# nrf54h20_engb_application register map
Vendor: Nordic Semiconductor; Series: nRF54h; File version: 1
CPU: CM33 r0p4, little endian, MPU, FPU, 3 interrupt priority bits, 480 interrupts, 8 SAU regions
Registers are 32-bit, read-write, reset 0x0 unless marked. A register's access mark holds for its fields unless they carry their own. Offsets are from the block's base; [hi:lo] are bit positions; lines under a group give offsets from that group; 'fields as' and 'values as' point back to an identical list.

## HSFLL_S — HSFLL
Base 0x5200D000
0x00 TASKS_START wo — Start the HSFLL
  [0] TASKS_START
    1=Trigger task
0x04 TASKS_STOP wo — Stop the HSFLL
  [0] TASKS_STOP
    1=Trigger task
0x10 TASKS_FREQMEAS wo — Start frequency measurement in software-controlled mode
  [0] TASKS_FREQMEAS
    1=Trigger task
0x14 TASKS_FREQCHANGE wo — Trigger frequency change
  [0] TASKS_FREQCHANGE
    1=Trigger task
0x100 EVENTS_STARTED — HSFLL started
  [0] EVENTS_STARTED
    0=NotGenerated (Event not generated); 1=Generated (Event generated)
0x104 EVENTS_STOPPED — HSFLL stopped
  [0] EVENTS_STOPPED
    values as EVENTS_STARTED.EVENTS_STARTED
0x10C EVENTS_FREQMDONE — Frequency measurement done
  [0] EVENTS_FREQMDONE
    values as EVENTS_STARTED.EVENTS_STARTED
0x110 EVENTS_FREQCHANGED — Frequency change done
  [0] EVENTS_FREQCHANGED
    values as EVENTS_STARTED.EVENTS_STARTED
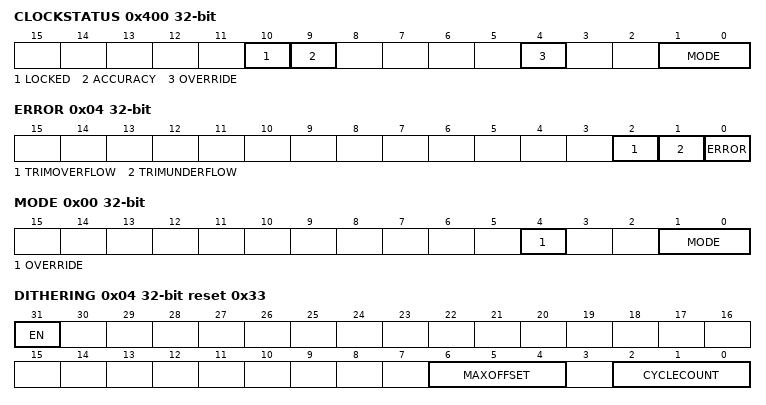
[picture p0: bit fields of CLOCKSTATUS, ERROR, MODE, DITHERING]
0x400 CLOCKSTATUS ro
  [10] LOCKED — The HSFLL lock status.
    0=Not locked to reference clock; 1=Locked to reference clock
  [9] ACCURACY — Clock accuracy.
    0=OutsideLimit (Clock accuracy is outside 2 percent.); 1=WithinLimit (Clock accuracy is within 2 percent.)
  [4] OVERRIDE — HSFLL Override mode.
    0=Disabled (Override mode disabled.); 1=Enabled (Override mode enabled.)
  [1:0] MODE — The HSFLL operating mode.
    0=Open loop mode; 1=Closed loop mode; 2=Bypass mode
0x420 FREQM group — Unspecified
  0x00 DONE ro — Frequency measurement done status
    [0] DONE — Measurement done.
      0=InProgress (Frequency measurement is in progress.); 1=Completed (Frequency measurement is completed.)
  0x04 ERROR ro — Frequency measurement error status
    [2] TRIMOVERFLOW — Overflow error status.
      1=OutsideLimit (Overflow); 0=WithinLimit (No overflow)
    [1] TRIMUNDERFLOW — Underflow error status.
      1=OutsideLimit (Underflow); 0=WithinLimit (No underflow)
    [0] ERROR — Trim error status.
      1=OutsideLimit (Frequency exceeded the accuracy 2 percent in closed loop mode.); 0=WithinLimit (Frequency stayed within accuracy 2 percent in closed loop mode.)
  0x08 MEAS ro — Frequency measurement
    [7:0] VALUE — Last frequency measurement value.
0x440 TRIM group — Unspecified
  0x00 VSUP reset 0x10 — Internal regulator voltage supply level trimming
    [4:0] VALUE — Trim value
  0x04 COARSE reset 0x4 — Coarse frequency trimming
    [9:0] VALUE — Coarse frequency trimming value.
  0x08 FINE reset 0x1E — Fine frequency trimming
    [10:0] VALUE — Fine frequency trimming value
  0x10 TCOEF — Temperature coefficient trimming
    [3:0] VALUE — Trim value.
0x460 CLOCKCTRL group — Unspecified
  0x00 MODE — Clock control
    [4] OVERRIDE — HSFLL override mode.
      values as CLOCKSTATUS.OVERRIDE
    [1:0] MODE — The HSFLL operating mode.
      0=Auto (The PCGC controls the mode automatically.); 1=Open loop mode; 2=Closed loop mode; 3=Bypass mode
  0x04 DITHERING reset 0x33 — Clock dithering configuration
    [31] EN — Enable the clock dithering
      0=Disabled (Clock dithering is disabled); 1=Enabled (Clock dithering is enabled)
    [6:4] MAXOFFSET — Maximum offset configuration for clock dithering
    [2:0] CYCLECOUNT — Cycle count configuration for clock dithering
  0x08 MULT reset 0x4 — Multiplication factor
    [4:0] VAL — Multiplication factor value. Valid range: 4 to 25. Output frequency is a multiplication of 16 MHz reference and the multiplication factor.
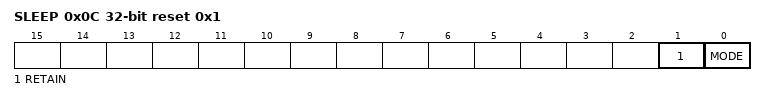
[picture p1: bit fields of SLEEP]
  0x0C SLEEP reset 0x1 — Sleep configuration
    [1] RETAIN
      0=Disabled (No retention while powered down); 1=Enabled (Retain all inputs while powered down)
    [0] MODE — HSFLL sleep mode.
      0=Normal mode operation; 1=Sleep (Power down the HSFLL core)
  0x10 RETAINFINETRIM — Fine trim retain control
    [0] RETAIN — Retain control
      0=NoRetain; 1=Retain control when HSFLL goes to open-loop mode
  0x14 OVERRIDELOCKED — Override the LOCKED signal
    [0] OVERRIDE
      0=NoOperation; 1=Override
  0x18 DITHERINIT — Clock dithering, configurable seed
    [31:0] SEED — Initial value for the PRBS
0x480 MIRROR reset 0x1 — Enable LOCK for mirrored registers
  [0] LOCK — Lock for mirrored registers
    0=Disabled (Lock disabled); 1=Enabled (Lock enabled)
